# ATmega4808 register map
Vendor: Atmel; File version: 1.0
CPU: other r0p0, little endian, no MPU, no FPU, 4 interrupt priority bits
Registers are 8-bit, read-write, reset 0x0 unless marked. A register's access mark holds for its fields unless they carry their own. Offsets are from the block's base; [hi:lo] are bit positions; {n}, {i} and the like mark numbered series; 'fields as' and 'values as' point back to an identical list.

## CCL — Configurable Custom Logic
Base 0x008001C0
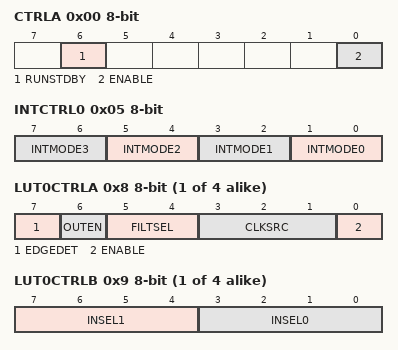
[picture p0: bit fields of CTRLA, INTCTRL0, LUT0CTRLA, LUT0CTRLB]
0x00 CTRLA — Control Register A
  [6] RUNSTDBY — Run in Standby
  [0] ENABLE
0x01 SEQCTRL0 — Sequential Control 0
  [2:0] SEQSEL0 — Sequential Selection
    0=DISABLE (Sequential logic disabled); 1=DFF (D FlipFlop); 2=JK (JK FlipFlop); 3=LATCH (D Latch); 4=RS (RS Latch)
0x02 SEQCTRL1 — Sequential Control 1
  [2:0] SEQSEL1 — Sequential Selection
    values as SEQCTRL0.SEQSEL0
0x05 INTCTRL0 — Interrupt Control 0
  [all] fields
    0=INTDISABLE (Interrupt disabled); 1=RISING (Sense rising edge); 2=FALLING (Sense falling edge); 3=BOTH (Sense both edges)
  [2n+1:2n] INTMODE{n} (n=0..3) — Interrupt Mode for LUT{n}
0x07 INTFLAGS — Interrupt Flags
  [3:0] INT
{0x8+4i} LUT{i}CTRLA (i=0..3) — LUT Control {i} A
  [7] EDGEDET — Edge Detection Enable
    0=DIS (Edge detector is disabled); 1=EN (Edge detector is enabled)
  [6] OUTEN — Output Enable
  [5:4] FILTSEL — Filter Selection
    0=DISABLE (Filter disabled); 1=SYNCH (Synchronizer enabled); 2=FILTER (Filter enabled)
  [3:1] CLKSRC — Clock Source Selection
    0=CLKPER (CLK_PER is clocking the LUT); 1=IN2 (IN[2] is clocking the LUT); 4=OSC20M (20MHz oscillator before prescaler is clocking the LUT); 5=OSCULP32K (32kHz oscillator is clocking the LUT); 6=OSCULP1K (1kHz (32kHz oscillator after DIV32) is clocking the LUT)
  [0] ENABLE — LUT Enable
{0x9+4i} LUT{i}CTRLB (i=0..3) — LUT Control {i} B
  [7:4] INSEL1 — LUT Input 1 Source Selection
    0=MASK (Masked input); 1=FEEDBACK (Feedback input source); 2=LINK (Linked LUT input source); 3=EVENTA (Event input source A); 4=EVENTB (Event input source B); 5=IO (IO pin LUTn-N1 input source); 6=AC0 (AC0 OUT input source); 8=USART1 (USART1 TXD input source); 9=SPI0 (SPI0 MOSI input source); 10=TCA0 (TCA0 WO1 input source); 12=TCB1 (TCB1 WO input source)
  [3:0] INSEL0 — LUT Input 0 Source Selection
    0=MASK (Masked input); 1=FEEDBACK (Feedback input source); 2=LINK (Linked LUT input source); 3=EVENTA (Event input source A); 4=EVENTB (Event input source B); 5=IO (IO pin LUTn-IN0 input source); 6=AC0 (AC0 OUT input source); 8=USART0 (USART0 TXD input source); 9=SPI0 (SPI0 MOSI input source); 10=TCA0 (TCA0 WO0 input source); 12=TCB0 (TCB0 WO input source)
{0xA+4i} LUT{i}CTRLC (i=0..3) — LUT Control {i} C
  [3:0] INSEL2 — LUT Input 2 Source Selection
    0=MASK (Masked input); 1=FEEDBACK (Feedback input source); 2=LINK (Linked LUT input source); 3=EVENTA (Event input source A); 4=EVENTB (Event input source B); 5=IO (IO pin LUTn-IN2 input source); 6=AC0 (AC0 OUT input source); 8=USART2 (USART2 TXD input source); 9=SPI0 (SPI0 SCK input source); 10=TCA0 (TCA0 WO2 input source); 12=TCB2 (TCB2 WO input source)
{0xB+4i} TRUTH{i} (i=0..3)
  [7:0] TRUTH — Truth Table

## CLKCTRL — Clock controller
Base 0x00800060
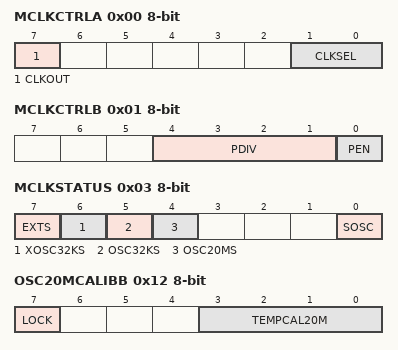
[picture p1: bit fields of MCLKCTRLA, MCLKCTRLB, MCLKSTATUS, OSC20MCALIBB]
0x00 MCLKCTRLA — MCLK Control A
  [7] CLKOUT — System clock out
  [1:0] CLKSEL — Clock select
    0=OSC20M (16/20MHz internal oscillator); 1=OSCULP32K (32.768kHz internal ultra low-power oscillator); 2=XOSC32K (32.768kHz external crystal oscillator); 3=EXTCLK (External clock)
0x01 MCLKCTRLB — MCLK Control B
  [4:1] PDIV — Prescaler division
    0=2X; 1=4X; 2=8X; 3=16X; 4=32X; 5=64X; 8=6X; 9=10X; 10=12X; 11=24X; 12=48X
  [0] PEN — Prescaler enable
0x02 MCLKLOCK
  [0] LOCKEN — Lock enable
0x03 MCLKSTATUS ro
  [7] EXTS — External Clock status
  [6] XOSC32KS — 32.768 kHz Crystal Oscillator status
  [5] OSC32KS — 32KHz oscillator status
  [4] OSC20MS — 20MHz oscillator status
  [0] SOSC — System Oscillator changing
0x10 OSC20MCTRLA — OSC20M Control A
  [1] RUNSTDBY — Run standby
0x11 OSC20MCALIBA — OSC20M Calibration A
  [6:0] CAL20M — Calibration
0x12 OSC20MCALIBB — OSC20M Calibration B
  [7] LOCK
  [3:0] TEMPCAL20M — Oscillator temperature coefficient
0x18 OSC32KCTRLA — OSC32K Control A
  [1] RUNSTDBY — Run standby
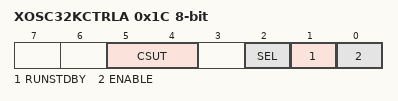
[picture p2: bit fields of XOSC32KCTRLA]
0x1C XOSC32KCTRLA — XOSC32K Control A
  [5:4] CSUT — Crystal startup time
    0=1K (1k cycles); 1=16K (16k cycles); 2=32K (32k cycles); 3=64K (64k cycles)
  [2] SEL — Select
  [1] RUNSTDBY — Run standby
  [0] ENABLE
